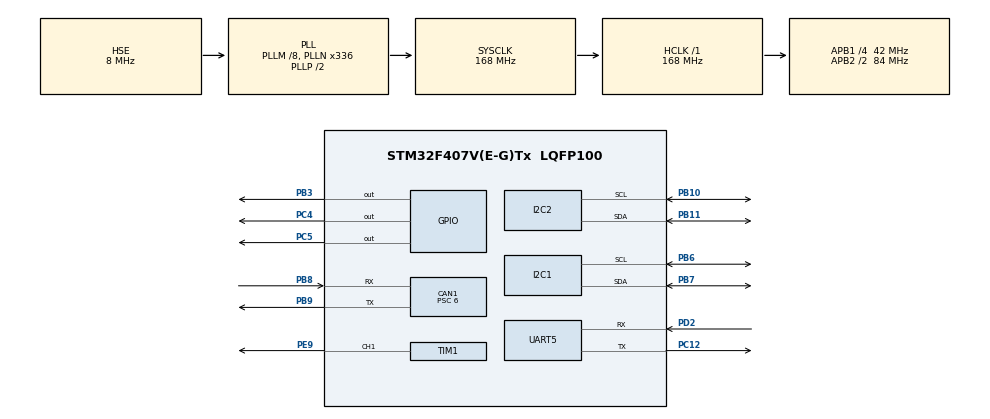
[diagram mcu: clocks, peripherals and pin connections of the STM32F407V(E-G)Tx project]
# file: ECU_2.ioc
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CAN1.BS1=CAN_BS1_11TQ
CAN1.BS2=CAN_BS2_2TQ
CAN1.CalculateBaudRate=500000
CAN1.CalculateTimeBit=2000
CAN1.CalculateTimeQuantum=142.85714285714286
CAN1.NART=ENABLE
CAN1.Prescaler=6
I2C2.I2C_Mode=I2C_Fast
Mcu.Family=STM32F4
Mcu.Name=STM32F407V(E-G)Tx
Mcu.Package=LQFP100
NVIC.CAN1_RX0_IRQn=true\:0\:0\:false\:false\:true\:true\:true\:true
NVIC.CAN1_SCE_IRQn=true\:0\:0\:false\:false\:true\:true\:true\:true
NVIC.CAN1_TX_IRQn=true\:0\:0\:false\:false\:true\:true\:true\:true
NVIC.PriorityGroup=NVIC_PRIORITYGROUP_4
NVIC.TIM3_IRQn=true\:15\:0\:false\:false\:true\:false\:true\:true
NVIC.TimeBase=TIM3_IRQn
NVIC.TimeBaseIP=TIM3
PB10.Mode=I2C
PB10.Signal=I2C2_SCL
PB11.Mode=I2C
PB11.Signal=I2C2_SDA
PB3.Signal=GPIO_Output
PB6.Mode=I2C
PB6.Signal=I2C1_SCL
PB7.Mode=I2C
PB7.Signal=I2C1_SDA
PB8.Mode=CAN_Activate
PB8.Signal=CAN1_RX
PB9.Mode=CAN_Activate
PB9.Signal=CAN1_TX
PC12.Mode=Asynchronous
PC12.Signal=UART5_TX
PC4.Signal=GPIO_Output
PC5.Signal=GPIO_Output
PD2.Mode=Asynchronous
PD2.Signal=UART5_RX
PE9.Signal=S_TIM1_CH1
PH0-OSC_IN.Mode=HSE-External-Oscillator
PH0-OSC_IN.Signal=RCC_OSC_IN
PH1-OSC_OUT.Mode=HSE-External-Oscillator
PH1-OSC_OUT.Signal=RCC_OSC_OUT
ProjectManager.HeapSize=0x200
ProjectManager.StackSize=0x400
ProjectManager.TargetToolchain=STM32CubeIDE
RCC.48MHZClocksFreq_Value=84000000
RCC.AHBFreq_Value=168000000
RCC.APB1CLKDivider=RCC_HCLK_DIV4
RCC.APB1Freq_Value=42000000
RCC.APB1TimFreq_Value=84000000
RCC.APB2CLKDivider=RCC_HCLK_DIV2
RCC.APB2Freq_Value=84000000
RCC.APB2TimFreq_Value=168000000
RCC.CortexFreq_Value=168000000
RCC.HCLKFreq_Value=168000000
RCC.HSE_VALUE=8000000
RCC.HSI_VALUE=16000000
RCC.LSE_VALUE=32768
RCC.PLLM=8
RCC.PLLN=336
RCC.PLLSourceVirtual=RCC_PLLSOURCE_HSE
RCC.SYSCLKFreq_VALUE=168000000
RCC.SYSCLKSource=RCC_SYSCLKSOURCE_PLLCLK
RCC.VCOOutputFreq_Value=336000000
SH.S_TIM1_CH1.0=TIM1_CH1,PWM Generation1 CH1
TIM1.AutoReloadPreload=TIM_AUTORELOAD_PRELOAD_ENABLE
TIM1.Channel-PWM\ Generation1\ CH1=TIM_CHANNEL_1
TIM1.Period=99
TIM1.Prescaler=167
TIM1.Pulse-PWM\ Generation1\ CH1=1000
UART5.VirtualMode=Asynchronous
VP_SYS_VS_tim3.Mode=TIM3
VP_TIM1_VS_ClockSourceINT.Mode=Internal
board=custom

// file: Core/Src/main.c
/* USER CODE BEGIN Header */
/**
  ******************************************************************************
  * @file           : main.c
  * @brief          : Main program body
  ******************************************************************************
  * @attention
  *
  * Copyright (c) 2026 STMicroelectronics.
  * All rights reserved.
  *
  * This software is licensed under terms that can be found in the LICENSE file
  * in the root directory of this software component.
  * If no LICENSE file comes with this software, it is provided AS-IS.
  *
  ******************************************************************************
  */
/* USER CODE END Header */
#include "main.h"

/* USER CODE BEGIN Includes */
#include <stdio.h>
#include <string.h>
#include"CAN_COMM.h"
#include"SENSOR_TOF.h"
#include "FreeRTOS.h"
#include "task.h"
#include "timers.h"
#include "queue.h"
#include "semphr.h"
#include "event_groups.h"
#include "SEGGER_SYSVIEW.h"
#include "freertos_tasks.h"
#include "OLED_DISPLAY.h"

/* USER CODE END Includes */

CAN_HandleTypeDef hcan1;

I2C_HandleTypeDef hi2c1;
I2C_HandleTypeDef hi2c2;

TIM_HandleTypeDef htim1;

UART_HandleTypeDef huart5;

void SystemClock_Config(void);
static void MX_GPIO_Init(void);
static void MX_CAN1_Init(void);
static void MX_UART5_Init(void);
static void MX_I2C1_Init(void);
static void MX_TIM1_Init(void);
static void MX_I2C2_Init(void);

int main(void)
{

  /* MCU Configuration--------------------------------------------------------*/

  /* Reset of all peripherals, Initializes the Flash interface and the Systick. */
  HAL_Init();

  /* Configure the system clock */
  SystemClock_Config();

  /* Initialize all configured peripherals */
  MX_GPIO_Init();
  MX_CAN1_Init();
  MX_UART5_Init();
  MX_I2C1_Init();
  MX_TIM1_Init();
  MX_I2C2_Init();
  OLED_Init();

  /* USER CODE BEGIN 2 */

  Motor_Init();
  Ramp_Init();
  //	Motor_Stop();
  CAN_Init();

  CAN_Headers();
  CAN_UART();

BaseType_t status;

  status = xTaskCreate(Ramp_Task,
                       "RAMP",
                       256,
                       NULL,
                       2,
                       NULL);

  status = xTaskCreate(DecisionTask,
                       "Decision",
                       256,
                       NULL,
                       3,
                       &DecisionTaskHandle);

  status = xTaskCreate(OLED_Task,
                       "OLED",
                       256,
                       NULL,
                       1,
                       &OLEDTaskHandle);

  HAL_UART_Transmit(&huart5,
                    (uint8_t *)"Before Scheduler\r\n",
                    18,
                    HAL_MAX_DELAY);
  vTaskStartScheduler();

}

void SystemClock_Config(void)
{
  RCC_OscInitTypeDef RCC_OscInitStruct = {0};
  RCC_ClkInitTypeDef RCC_ClkInitStruct = {0};

  /** Configure the main internal regulator output voltage
  */
  __HAL_RCC_PWR_CLK_ENABLE();
  __HAL_PWR_VOLTAGESCALING_CONFIG(PWR_REGULATOR_VOLTAGE_SCALE1);

  /** Initializes the RCC Oscillators according to the specified parameters
  * in the RCC_OscInitTypeDef structure.
  */
  RCC_OscInitStruct.OscillatorType = RCC_OSCILLATORTYPE_HSE;
  RCC_OscInitStruct.HSEState = RCC_HSE_ON;
  RCC_OscInitStruct.PLL.PLLState = RCC_PLL_ON;
  RCC_OscInitStruct.PLL.PLLSource = RCC_PLLSOURCE_HSE;
  RCC_OscInitStruct.PLL.PLLM = 8;
  RCC_OscInitStruct.PLL.PLLN = 336;
  RCC_OscInitStruct.PLL.PLLP = RCC_PLLP_DIV2;
  RCC_OscInitStruct.PLL.PLLQ = 4;
  if (HAL_RCC_OscConfig(&RCC_OscInitStruct) != HAL_OK)
  {
    Error_Handler();
  }

  /** Initializes the CPU, AHB and APB buses clocks
  */
  RCC_ClkInitStruct.ClockType = RCC_CLOCKTYPE_HCLK|RCC_CLOCKTYPE_SYSCLK
                              |RCC_CLOCKTYPE_PCLK1|RCC_CLOCKTYPE_PCLK2;
  RCC_ClkInitStruct.SYSCLKSource = RCC_SYSCLKSOURCE_PLLCLK;
  RCC_ClkInitStruct.AHBCLKDivider = RCC_SYSCLK_DIV1;
  RCC_ClkInitStruct.APB1CLKDivider = RCC_HCLK_DIV4;
  RCC_ClkInitStruct.APB2CLKDivider = RCC_HCLK_DIV2;

  if (HAL_RCC_ClockConfig(&RCC_ClkInitStruct, FLASH_LATENCY_5) != HAL_OK)
  {
    Error_Handler();
  }
}

static void MX_CAN1_Init(void)
{

  hcan1.Instance = CAN1;
  hcan1.Init.Prescaler = 6;
  hcan1.Init.Mode = CAN_MODE_NORMAL;
  hcan1.Init.SyncJumpWidth = CAN_SJW_1TQ;
  hcan1.Init.TimeSeg1 = CAN_BS1_11TQ;
  hcan1.Init.TimeSeg2 = CAN_BS2_2TQ;
  hcan1.Init.TimeTriggeredMode = DISABLE;
  hcan1.Init.AutoBusOff = DISABLE;
  hcan1.Init.AutoWakeUp = DISABLE;
  hcan1.Init.AutoRetransmission = ENABLE;
  hcan1.Init.ReceiveFifoLocked = DISABLE;
  hcan1.Init.TransmitFifoPriority = DISABLE;
  if (HAL_CAN_Init(&hcan1) != HAL_OK)
  {
    Error_Handler();
  }

}

static void MX_I2C1_Init(void)
{

  hi2c1.Instance = I2C1;
  hi2c1.Init.ClockSpeed = 100000;
  hi2c1.Init.DutyCycle = I2C_DUTYCYCLE_2;
  hi2c1.Init.OwnAddress1 = 0;
  hi2c1.Init.AddressingMode = I2C_ADDRESSINGMODE_7BIT;
  hi2c1.Init.DualAddressMode = I2C_DUALADDRESS_DISABLE;
  hi2c1.Init.OwnAddress2 = 0;
  hi2c1.Init.GeneralCallMode = I2C_GENERALCALL_DISABLE;
  hi2c1.Init.NoStretchMode = I2C_NOSTRETCH_DISABLE;
  if (HAL_I2C_Init(&hi2c1) != HAL_OK)
  {
    Error_Handler();
  }

}

static void MX_I2C2_Init(void)
{

  hi2c2.Instance = I2C2;
  hi2c2.Init.ClockSpeed = 400000;
  hi2c2.Init.DutyCycle = I2C_DUTYCYCLE_2;
  hi2c2.Init.OwnAddress1 = 0;
  hi2c2.Init.AddressingMode = I2C_ADDRESSINGMODE_7BIT;
  hi2c2.Init.DualAddressMode = I2C_DUALADDRESS_DISABLE;
  hi2c2.Init.OwnAddress2 = 0;
  hi2c2.Init.GeneralCallMode = I2C_GENERALCALL_DISABLE;
  hi2c2.Init.NoStretchMode = I2C_NOSTRETCH_DISABLE;
  if (HAL_I2C_Init(&hi2c2) != HAL_OK)
  {
    Error_Handler();
  }

}

static void MX_TIM1_Init(void)
{

  TIM_ClockConfigTypeDef sClockSourceConfig = {0};
  TIM_MasterConfigTypeDef sMasterConfig = {0};
  TIM_OC_InitTypeDef sConfigOC = {0};
  TIM_BreakDeadTimeConfigTypeDef sBreakDeadTimeConfig = {0};

  htim1.Instance = TIM1;
  htim1.Init.Prescaler = 167;
  htim1.Init.CounterMode = TIM_COUNTERMODE_UP;
  htim1.Init.Period = 99;
  htim1.Init.ClockDivision = TIM_CLOCKDIVISION_DIV1;
  htim1.Init.RepetitionCounter = 0;
  htim1.Init.AutoReloadPreload = TIM_AUTORELOAD_PRELOAD_ENABLE;
  if (HAL_TIM_Base_Init(&htim1) != HAL_OK)
  {
    Error_Handler();
  }
  sClockSourceConfig.ClockSource = TIM_CLOCKSOURCE_INTERNAL;
  if (HAL_TIM_ConfigClockSource(&htim1, &sClockSourceConfig) != HAL_OK)
  {
    Error_Handler();
  }
  if (HAL_TIM_PWM_Init(&htim1) != HAL_OK)
  {
    Error_Handler();
  }
  sMasterConfig.MasterOutputTrigger = TIM_TRGO_RESET;
  sMasterConfig.MasterSlaveMode = TIM_MASTERSLAVEMODE_DISABLE;
  if (HAL_TIMEx_MasterConfigSynchronization(&htim1, &sMasterConfig) != HAL_OK)
  {
    Error_Handler();
  }
  sConfigOC.OCMode = TIM_OCMODE_PWM1;
  sConfigOC.Pulse = 0;
  sConfigOC.OCPolarity = TIM_OCPOLARITY_HIGH;
  sConfigOC.OCNPolarity = TIM_OCNPOLARITY_HIGH;
  sConfigOC.OCFastMode = TIM_OCFAST_DISABLE;
  sConfigOC.OCIdleState = TIM_OCIDLESTATE_RESET;
  sConfigOC.OCNIdleState = TIM_OCNIDLESTATE_RESET;
  if (HAL_TIM_PWM_ConfigChannel(&htim1, &sConfigOC, TIM_CHANNEL_1) != HAL_OK)
  {
    Error_Handler();
  }
  sBreakDeadTimeConfig.OffStateRunMode = TIM_OSSR_DISABLE;
  sBreakDeadTimeConfig.OffStateIDLEMode = TIM_OSSI_DISABLE;
  sBreakDeadTimeConfig.LockLevel = TIM_LOCKLEVEL_OFF;
  sBreakDeadTimeConfig.DeadTime = 0;
  sBreakDeadTimeConfig.BreakState = TIM_BREAK_DISABLE;
  sBreakDeadTimeConfig.BreakPolarity = TIM_BREAKPOLARITY_HIGH;
  sBreakDeadTimeConfig.AutomaticOutput = TIM_AUTOMATICOUTPUT_DISABLE;
  if (HAL_TIMEx_ConfigBreakDeadTime(&htim1, &sBreakDeadTimeConfig) != HAL_OK)
  {
    Error_Handler();
  }
  HAL_TIM_MspPostInit(&htim1);

}

static void MX_UART5_Init(void)
{

  huart5.Instance = UART5;
  huart5.Init.BaudRate = 115200;
  huart5.Init.WordLength = UART_WORDLENGTH_8B;
  huart5.Init.StopBits = UART_STOPBITS_1;
  huart5.Init.Parity = UART_PARITY_NONE;
  huart5.Init.Mode = UART_MODE_TX_RX;
  huart5.Init.HwFlowCtl = UART_HWCONTROL_NONE;
  huart5.Init.OverSampling = UART_OVERSAMPLING_16;
  if (HAL_UART_Init(&huart5) != HAL_OK)
  {
    Error_Handler();
  }

}

static void MX_GPIO_Init(void)
{
  GPIO_InitTypeDef GPIO_InitStruct = {0};

  /* GPIO Ports Clock Enable */
  __HAL_RCC_GPIOH_CLK_ENABLE();
  __HAL_RCC_GPIOC_CLK_ENABLE();
  __HAL_RCC_GPIOE_CLK_ENABLE();
  __HAL_RCC_GPIOB_CLK_ENABLE();
  __HAL_RCC_GPIOD_CLK_ENABLE();

  /*Configure GPIO pin Output Level */
  HAL_GPIO_WritePin(GPIOC, GPIO_PIN_4|GPIO_PIN_5, GPIO_PIN_RESET);

  /*Configure GPIO pin Output Level */
  HAL_GPIO_WritePin(GPIOB, GPIO_PIN_3, GPIO_PIN_RESET);

  /*Configure GPIO pins : PC4 PC5 */
  GPIO_InitStruct.Pin = GPIO_PIN_4|GPIO_PIN_5;
  GPIO_InitStruct.Mode = GPIO_MODE_OUTPUT_PP;
  GPIO_InitStruct.Pull = GPIO_NOPULL;
  GPIO_InitStruct.Speed = GPIO_SPEED_FREQ_LOW;
  HAL_GPIO_Init(GPIOC, &GPIO_InitStruct);

  /*Configure GPIO pin : PB3 */
  GPIO_InitStruct.Pin = GPIO_PIN_3;
  GPIO_InitStruct.Mode = GPIO_MODE_OUTPUT_PP;
  GPIO_InitStruct.Pull = GPIO_NOPULL;
  GPIO_InitStruct.Speed = GPIO_SPEED_FREQ_LOW;
  HAL_GPIO_Init(GPIOB, &GPIO_InitStruct);

}

void HAL_TIM_PeriodElapsedCallback(TIM_HandleTypeDef *htim)
{
  if (htim->Instance == TIM3)
  {
    HAL_IncTick();
  }
}

void Error_Handler(void)
{
  __disable_irq();
  while (1)
  {
  }
}
